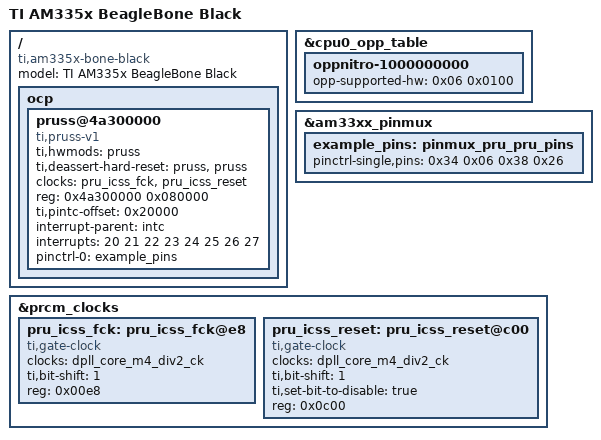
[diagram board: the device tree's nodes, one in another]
/*
 * Copyright (C) 2012 Texas Instruments Incorporated - http://www.ti.com/
 *
 * This program is free software; you can redistribute it and/or modify
 * it under the terms of the GNU General Public License version 2 as
 * published by the Free Software Foundation.
 */
/dts-v1/;

#include "am33xx.dtsi"
#include "am335x-bone-common.dtsi"
#include "am335x-boneblack-common.dtsi"

/ {
	model = "TI AM335x BeagleBone Black";
	compatible = "ti,am335x-bone-black", "ti,am335x-bone", "ti,am33xx";
};

&cpu0_opp_table {
	/*
	 * All PG 2.0 silicon may not support 1GHz but some of the early
	 * BeagleBone Blacks have PG 2.0 silicon which is guaranteed
	 * to support 1GHz OPP so enable it for PG 2.0 on this board.
	 */
	oppnitro-1000000000 {
		opp-supported-hw = <0x06 0x0100>;
	};
};

// Add pin mux for PRU test
&am33xx_pinmux {
    example_pins: pinmux_pru_pru_pins {

       // The offset and mode for pins P8_11 and P8_16 also come from the table linked above.
       //
       // That table gives offset 0x34 for P8_11, and 0x38 for P8_16.
       // It also shows us we want pinmux mode 6 for P8_11 in output mode,
       // and again pinmux mode 6 for P8_16 in input mode.
       //
       // Table 9-60 in the TRM: http://www.ti.com/lit/ug/spruh73l/spruh73l.pdf
       // helps us calculate the rest of the configuration value.
       //
       // For P8_11, the other fields are all 0, so the value is just 0x06.
       //
       // For P8_16, we want it to be an input, so we also set bit 5, yielding
       // a value of 0x26. We could also set bits 3 and 4 to enable a pullup
       // or pulldown.
       pinctrl-single,pins = <
         0x34 0x06
         0x38 0x26
       >;
    };
};

// Define PRU ICSS clock and reset signal as clock
&prcm_clocks {
    pru_icss_fck: pru_icss_fck@e8 {
        #clock-cells = <0>;
        compatible = "ti,gate-clock";
        clocks = <&dpll_core_m4_div2_ck>;
        ti,bit-shift = <1>;
        reg = <0x00e8>;
    };
    pru_icss_reset: pru_icss_reset@c00 {
        #clock-cells = <0>;
        compatible = "ti,gate-clock";
        clocks = <&dpll_core_m4_div2_ck>;
        ti,bit-shift = <1>;
        ti,set-bit-to-disable = "true";
        reg = <0x0c00>;
    };
};

/ {
    ocp {
        pruss@4a300000 {
            status = "okay";
            compatible = "ti,pruss-v1";
            ti,hwmods = "pruss";
            ti,deassert-hard-reset = "pruss", "pruss";
            clocks = <&pru_icss_fck>, <&pru_icss_reset>;
            clock-names = "pruss", "reset";
            reg = <0x4a300000 0x080000>;
            ti,pintc-offset = <0x20000>;
            interrupt-parent = <&intc>;
            interrupts = <20 21 22 23 24 25 26 27>;
            pinctrl-names = "default";
            pinctrl-0 = <&example_pins>;
        };
    };
};
